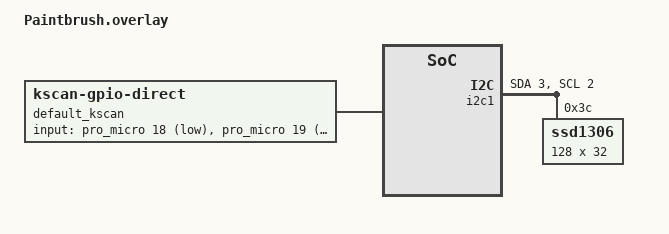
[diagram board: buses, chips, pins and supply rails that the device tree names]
&i2c1 {
    status = "okay";
    scl-pin = <2>;  // GPIO pin for SCL
    sda-pin = <3>;  // GPIO pin for SDA

    display: oled_display {
        compatible = "ssd1306";
        label = "SSD1306";
        reg = <0x3C>;  // I2C address of the OLED
        width = <128>;
        height = <32>;
    };
};

/ {
	chosen {
		zmk,kscan = &default_kscan;
	};

	default_kscan: kscan {
		compatible = "zmk,kscan-gpio-direct";
		label = "default_kscan";

		input-gpios
			= <&pro_micro 18 (GPIO_ACTIVE_LOW | GPIO_PULL_UP)>
            , <&pro_micro 19 (GPIO_ACTIVE_LOW | GPIO_PULL_UP)>
            , <&pro_micro 20 (GPIO_ACTIVE_LOW | GPIO_PULL_UP)>
            , <&pro_micro 21 (GPIO_ACTIVE_LOW | GPIO_PULL_UP)>
            , <&pro_micro 10 (GPIO_ACTIVE_LOW | GPIO_PULL_UP)>
            , <&pro_micro 16 (GPIO_ACTIVE_LOW | GPIO_PULL_UP)>
            , <&pro_micro 14 (GPIO_ACTIVE_LOW | GPIO_PULL_UP)>
            , <&pro_micro 15 (GPIO_ACTIVE_LOW | GPIO_PULL_UP)>
			;
	};
};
